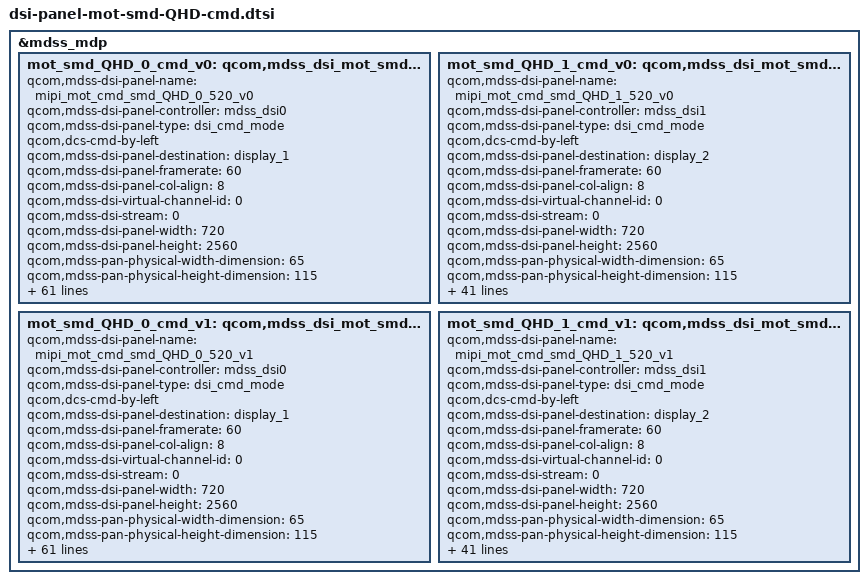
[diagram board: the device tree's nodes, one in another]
/* Copyright (c) 2012-2013, The Linux Foundation. All rights reserved.
 * Copyright (c) 2014 Motorola Mobility LLC
 *
 * This program is free software; you can redistribute it and/or modify
 * it under the terms of the GNU General Public License version 2 and
 * only version 2 as published by the Free Software Foundation.
 *
 * This program is distributed in the hope that it will be useful,
 * but WITHOUT ANY WARRANTY; without even the implied warranty of
 * MERCHANTABILITY or FITNESS FOR A PARTICULAR PURPOSE.  See the
 * GNU General Public License for more details.
 */

&mdss_mdp {
	mot_smd_QHD_0_cmd_v0: qcom,mdss_dsi_mot_smd_QHD_dualmipi0_cmd_v0 {
		qcom,mdss-dsi-panel-name = "mipi_mot_cmd_smd_QHD_0_520_v0";
		qcom,mdss-dsi-panel-controller = <&mdss_dsi0>;
		qcom,mdss-dsi-panel-type = "dsi_cmd_mode";
		qcom,dcs-cmd-by-left;
		qcom,mdss-dsi-panel-destination = "display_1";
		qcom,mdss-dsi-panel-framerate = <60>;
		qcom,mdss-dsi-panel-col-align = <8>;
		qcom,mdss-dsi-virtual-channel-id = <0>;
		qcom,mdss-dsi-stream = <0>;
		qcom,mdss-dsi-panel-width = <720>;
		qcom,mdss-dsi-panel-height = <2560>;
		qcom,mdss-pan-physical-width-dimension = <65>;
		qcom,mdss-pan-physical-height-dimension = <115>;
		qcom,mdss-dsi-panel-clockrate = <830000000>;
		qcom,mdss-dsi-h-front-porch = <120>;
		qcom,mdss-dsi-h-back-porch = <44>;
		qcom,mdss-dsi-h-pulse-width = <16>;
		qcom,mdss-dsi-h-sync-skew = <0>;
		qcom,mdss-dsi-v-back-porch = <4>;
		qcom,mdss-dsi-v-front-porch = <8>;
		qcom,mdss-dsi-v-pulse-width = <4>;
		qcom,mdss-dsi-h-left-border = <0>;
		qcom,mdss-dsi-h-right-border = <0>;
		qcom,mdss-dsi-v-top-border = <0>;
		qcom,mdss-dsi-v-bottom-border = <0>;
		qcom,mdss-dsi-bpp = <24>;
		qcom,mdss-dsi-underflow-color = <0xff>;
		qcom,mdss-dsi-border-color = <0>;
		qcom,mdss-dsi-h-sync-pulse = <0>;
		qcom,mdss-dsi-traffic-mode = "non_burst_sync_event";
		qcom,mdss-dsi-bllp-eof-power-mode;
		qcom,mdss-dsi-bllp-power-mode;
		qcom,mdss-dsi-lane-0-state;
		qcom,mdss-dsi-lane-1-state;
		qcom,mdss-dsi-lane-2-state;
		qcom,mdss-dsi-lane-3-state;
		qcom,mdss-dsi-tx-eot-append;
		qcom,mdss-dsi-panel-timings = [DB 34 22 00 62 66 28 36 2B 03
									04 00];

		qcom,mdss-dsi-hbm-on-command = [
			/* HBM setting in 2 MSB bits of reg 53 */
			15 01 00 00 00 00 02 53 e0];
		qcom,mdss-dsi-hbm-off-command = [
			15 01 00 00 00 00 02 53 20];

		qcom,mdss-dsi-reset-sequence = <1 11>;
		qcom,mdss-dsi-dis-reset-sequence = <0 3>;
		qcom,mdss-dsi-lp11-init;
		qcom,mdss-dsi-t-clk-post = <0x03>;
		qcom,mdss-dsi-t-clk-pre = <0x29>;
		qcom,mdss-dsi-bl-max-level = <255>;
		qcom,mdss-dsi-dma-trigger = "trigger_sw";
		qcom,mdss-dsi-mdp-trigger = "none";
		qcom,mdss-dsi-bl-pmic-control-type = "bl_ctrl_dcs";
		qcom,mdss-dsi-te-pin-select = <1>;
		qcom,mdss-dsi-te-v-sync-rd-ptr-irq-line = <0x2c>;
		qcom,mdss-dsi-te-v-sync-continues-lines = <0x3c>;
		qcom,mdss-dsi-te-dcs-command = <1>;
		qcom,mdss-dsi-te-check-enable;
		qcom,mdss-dsi-te-using-te-pin;
		qcom,mdss-dsi-on-command = [
			/* Unlock level 2 commands */
			39 01 00 00 01 00 03 F0 5A 5A
			/* Unlock level 3 commands */
			39 01 00 00 01 00 03 FC 5A 5A
			/* Adjust memory scan time */
			39 01 00 00 01 00 05 FF 00 00 20 00
			/* exit sleep mode */
			05 01 00 00 78 00 02 11 00
			/* enable_te */
			15 01 00 00 01 00 02 35 00
			/* disp_ctrl */
			39 01 00 00 01 00 02 53 20
			/* brightness_ctrl */
			15 01 00 00 01 00 02 51 00
			/* acl_enable_disable_settings */
			39 01 00 00 01 00 02 55 03
			/* Set index for P9 */
			39 01 00 00 01 00 02 B0 08
			/* Turn on memory retention */
			39 01 00 00 01 00 02 F4 03
			/* viewable region */
			39 01 00 00 00 00 05 30 00 00 09 ff
			/* normal col */
			39 01 00 00 00 00 05 2a 00 00 05 9f
			/* normal row */
			39 01 00 00 00 00 05 2b 00 00 09 ff
			/* display on */
			05 01 00 00 00 00 01 29];
		qcom,mdss-dsi-on-command-state = "dsi_lp_mode";
		qcom,mdss-dsi-off-command = [
			/* display_off */
			05 01 00 00 01 00 02 28 00
			/* enter sleep mode */
			05 01 00 00 78 00 02 10 00];
		qcom,mdss-dsi-off-command-state = "dsi_hs_mode";

		qcom,esd-check-enabled;
		qcom,mdss-dsi-panel-status-check-mode = "reg_read";
		qcom,mdss-dsi-panel-status-command = [06 01 00 01 00 00 01 0A];
		qcom,mdss-dsi-panel-status-command-state = "dsi_hs_mode";
		qcom,mdss-dsi-panel-status-value = <0x9c>;

	};

	mot_smd_QHD_1_cmd_v0: qcom,mdss_dsi_mot_smd_QHD_dualmipi1_cmd_v0 {
		qcom,mdss-dsi-panel-name = "mipi_mot_cmd_smd_QHD_1_520_v0";
		qcom,mdss-dsi-panel-controller = <&mdss_dsi1>;
		qcom,mdss-dsi-panel-type = "dsi_cmd_mode";
		qcom,dcs-cmd-by-left;
		qcom,mdss-dsi-panel-destination = "display_2";
		qcom,mdss-dsi-panel-framerate = <60>;
		qcom,mdss-dsi-panel-col-align = <8>;
		qcom,mdss-dsi-virtual-channel-id = <0>;
		qcom,mdss-dsi-stream = <0>;
		qcom,mdss-dsi-panel-width = <720>;
		qcom,mdss-dsi-panel-height = <2560>;
		qcom,mdss-pan-physical-width-dimension = <65>;
		qcom,mdss-pan-physical-height-dimension = <115>;
		qcom,mdss-dsi-panel-clockrate = <830000000>;
		qcom,mdss-dsi-h-front-porch = <120>;
		qcom,mdss-dsi-h-back-porch = <44>;
		qcom,mdss-dsi-h-pulse-width = <16>;
		qcom,mdss-dsi-h-sync-skew = <0>;
		qcom,mdss-dsi-v-back-porch = <4>;
		qcom,mdss-dsi-v-front-porch = <8>;
		qcom,mdss-dsi-v-pulse-width = <4>;
		qcom,mdss-dsi-h-left-border = <0>;
		qcom,mdss-dsi-h-right-border = <0>;
		qcom,mdss-dsi-v-top-border = <0>;
		qcom,mdss-dsi-v-bottom-border = <0>;
		qcom,mdss-dsi-bpp = <24>;
		qcom,mdss-dsi-underflow-color = <0xff>;
		qcom,mdss-dsi-border-color = <0>;

		qcom,mdss-dsi-h-sync-pulse = <0>;
		qcom,mdss-dsi-traffic-mode = "non_burst_sync_event";
		qcom,mdss-dsi-bllp-eof-power-mode;
		qcom,mdss-dsi-bllp-power-mode;
		qcom,mdss-dsi-lane-0-state;
		qcom,mdss-dsi-lane-1-state;
		qcom,mdss-dsi-lane-2-state;
		qcom,mdss-dsi-lane-3-state;
		qcom,mdss-dsi-tx-eot-append;
		qcom,mdss-dsi-panel-timings = [DB 34 22 00 62 66 28 36 2B 03
									04 00];
		qcom,mdss-dsi-lp11-init;
		qcom,mdss-dsi-t-clk-post = <0x03>;
		qcom,mdss-dsi-t-clk-pre = <0x29>;
		qcom,mdss-dsi-bl-max-level = <255>;
		qcom,mdss-dsi-dma-trigger = "trigger_sw";
		qcom,mdss-dsi-mdp-trigger = "none";
		qcom,mdss-dsi-bl-pmic-control-type = "bl_ctrl_dcs";
		qcom,mdss-dsi-te-pin-select = <1>;
		qcom,mdss-dsi-te-v-sync-rd-ptr-irq-line = <0x2c>;
		qcom,mdss-dsi-te-v-sync-continues-lines = <0x3c>;
		qcom,mdss-dsi-te-dcs-command = <1>;
		qcom,mdss-dsi-te-check-enable;
		qcom,mdss-dsi-te-using-te-pin;
	};

	mot_smd_QHD_0_cmd_v1: qcom,mdss_dsi_mot_smd_QHD_dualmipi0_cmd_v1 {
		qcom,mdss-dsi-panel-name = "mipi_mot_cmd_smd_QHD_0_520_v1";
		qcom,mdss-dsi-panel-controller = <&mdss_dsi0>;
		qcom,mdss-dsi-panel-type = "dsi_cmd_mode";
		qcom,dcs-cmd-by-left;
		qcom,mdss-dsi-panel-destination = "display_1";
		qcom,mdss-dsi-panel-framerate = <60>;
		qcom,mdss-dsi-panel-col-align = <8>;
		qcom,mdss-dsi-virtual-channel-id = <0>;
		qcom,mdss-dsi-stream = <0>;
		qcom,mdss-dsi-panel-width = <720>;
		qcom,mdss-dsi-panel-height = <2560>;
		qcom,mdss-pan-physical-width-dimension = <65>;
		qcom,mdss-pan-physical-height-dimension = <115>;
		qcom,mdss-dsi-panel-clockrate = <830000000>;
		qcom,mdss-dsi-h-front-porch = <120>;
		qcom,mdss-dsi-h-back-porch = <44>;
		qcom,mdss-dsi-h-pulse-width = <16>;
		qcom,mdss-dsi-h-sync-skew = <0>;
		qcom,mdss-dsi-v-back-porch = <4>;
		qcom,mdss-dsi-v-front-porch = <8>;
		qcom,mdss-dsi-v-pulse-width = <4>;
		qcom,mdss-dsi-h-left-border = <0>;
		qcom,mdss-dsi-h-right-border = <0>;
		qcom,mdss-dsi-v-top-border = <0>;
		qcom,mdss-dsi-v-bottom-border = <0>;
		qcom,mdss-dsi-bpp = <24>;
		qcom,mdss-dsi-underflow-color = <0xff>;
		qcom,mdss-dsi-border-color = <0>;
		qcom,mdss-dsi-h-sync-pulse = <0>;
		qcom,mdss-dsi-traffic-mode = "non_burst_sync_event";
		qcom,mdss-dsi-bllp-eof-power-mode;
		qcom,mdss-dsi-bllp-power-mode;
		qcom,mdss-dsi-lane-0-state;
		qcom,mdss-dsi-lane-1-state;
		qcom,mdss-dsi-lane-2-state;
		qcom,mdss-dsi-lane-3-state;
		qcom,mdss-dsi-tx-eot-append;
		qcom,mdss-dsi-panel-timings = [DB 34 22 00 62 66 28 36 2B 03
									04 00];

		qcom,mdss-dsi-hbm-on-command = [
			/* HBM setting in 2 MSB bits of reg 53 */
			15 01 00 00 00 00 02 53 e0];
		qcom,mdss-dsi-hbm-off-command = [
			15 01 00 00 00 00 02 53 20];

		qcom,mdss-dsi-reset-sequence = <1 11>;
		qcom,mdss-dsi-dis-reset-sequence = <0 3>;
		qcom,mdss-dsi-lp11-init;
		qcom,mdss-dsi-t-clk-post = <0x03>;
		qcom,mdss-dsi-t-clk-pre = <0x29>;
		qcom,mdss-dsi-bl-max-level = <255>;
		qcom,mdss-dsi-dma-trigger = "trigger_sw";
		qcom,mdss-dsi-mdp-trigger = "none";
		qcom,mdss-dsi-bl-pmic-control-type = "bl_ctrl_dcs";
		qcom,mdss-dsi-te-pin-select = <1>;
		qcom,mdss-dsi-te-v-sync-rd-ptr-irq-line = <0x2c>;
		qcom,mdss-dsi-te-v-sync-continues-lines = <0x3c>;
		qcom,mdss-dsi-te-dcs-command = <1>;
		qcom,mdss-dsi-te-check-enable;
		qcom,mdss-dsi-te-using-te-pin;
		qcom,mdss-dsi-on-command = [
			/* exit sleep mode */
			05 01 00 00 78 00 02 11 00
			/* enable_te */
			15 01 00 00 01 00 02 35 00
			/* disp_ctrl */
			39 01 00 00 01 00 02 53 20
			/* brightness_ctrl */
			15 01 00 00 01 00 02 51 00
			/* acl_enable_disable_settings */
			39 01 00 00 01 00 02 55 03
			/* Unlock level 2 commands */
			39 01 00 00 01 00 03 F0 5A 5A
			/* Set index for P9 */
			39 01 00 00 01 00 02 B0 08
			/* Turn on memory retention */
			39 01 00 00 01 00 02 F4 03
			/* viewable region */
			39 01 00 00 00 00 05 30 00 00 09 ff
			/* normal col */
			39 01 00 00 00 00 05 2a 00 00 05 9f
			/* normal row */
			39 01 00 00 00 00 05 2b 00 00 09 ff
			/* display on */
			29 01 00 00 00 00 02 29 00];
		qcom,mdss-dsi-on-command-state = "dsi_lp_mode";
		qcom,mdss-dsi-off-command = [
			/* display_off */
			05 01 00 00 01 00 02 28 00
			/* enter sleep mode */
			05 01 00 00 78 00 02 10 00];
		qcom,mdss-dsi-off-command-state = "dsi_hs_mode";

                qcom,esd-check-enabled;
                qcom,mdss-dsi-panel-status-check-mode = "reg_read";
                qcom,mdss-dsi-panel-status-command = [06 01 00 01 00 00 01 0A];
                qcom,mdss-dsi-panel-status-command-state = "dsi_hs_mode";
                qcom,mdss-dsi-panel-status-value = <0x9c>;
	};

	mot_smd_QHD_1_cmd_v1: qcom,mdss_dsi_mot_smd_QHD_dualmipi1_cmd_v1 {
		qcom,mdss-dsi-panel-name = "mipi_mot_cmd_smd_QHD_1_520_v1";
		qcom,mdss-dsi-panel-controller = <&mdss_dsi1>;
		qcom,mdss-dsi-panel-type = "dsi_cmd_mode";
		qcom,dcs-cmd-by-left;
		qcom,mdss-dsi-panel-destination = "display_2";
		qcom,mdss-dsi-panel-framerate = <60>;
		qcom,mdss-dsi-panel-col-align = <8>;
		qcom,mdss-dsi-virtual-channel-id = <0>;
		qcom,mdss-dsi-stream = <0>;
		qcom,mdss-dsi-panel-width = <720>;
		qcom,mdss-dsi-panel-height = <2560>;
		qcom,mdss-pan-physical-width-dimension = <65>;
		qcom,mdss-pan-physical-height-dimension = <115>;
		qcom,mdss-dsi-panel-clockrate = <830000000>;
		qcom,mdss-dsi-h-front-porch = <120>;
		qcom,mdss-dsi-h-back-porch = <44>;
		qcom,mdss-dsi-h-pulse-width = <16>;
		qcom,mdss-dsi-h-sync-skew = <0>;
		qcom,mdss-dsi-v-back-porch = <4>;
		qcom,mdss-dsi-v-front-porch = <8>;
		qcom,mdss-dsi-v-pulse-width = <4>;
		qcom,mdss-dsi-h-left-border = <0>;
		qcom,mdss-dsi-h-right-border = <0>;
		qcom,mdss-dsi-v-top-border = <0>;
		qcom,mdss-dsi-v-bottom-border = <0>;
		qcom,mdss-dsi-bpp = <24>;
		qcom,mdss-dsi-underflow-color = <0xff>;
		qcom,mdss-dsi-border-color = <0>;

		qcom,mdss-dsi-h-sync-pulse = <0>;
		qcom,mdss-dsi-traffic-mode = "non_burst_sync_event";
		qcom,mdss-dsi-bllp-eof-power-mode;
		qcom,mdss-dsi-bllp-power-mode;
		qcom,mdss-dsi-lane-0-state;
		qcom,mdss-dsi-lane-1-state;
		qcom,mdss-dsi-lane-2-state;
		qcom,mdss-dsi-lane-3-state;
		qcom,mdss-dsi-tx-eot-append;
		qcom,mdss-dsi-panel-timings = [DB 34 22 00 62 66 28 36 2B 03
									04 00];
		qcom,mdss-dsi-lp11-init;
		qcom,mdss-dsi-t-clk-post = <0x03>;
		qcom,mdss-dsi-t-clk-pre = <0x29>;
		qcom,mdss-dsi-bl-max-level = <255>;
		qcom,mdss-dsi-dma-trigger = "trigger_sw";
		qcom,mdss-dsi-mdp-trigger = "none";
		qcom,mdss-dsi-bl-pmic-control-type = "bl_ctrl_dcs";
		qcom,mdss-dsi-te-pin-select = <1>;
		qcom,mdss-dsi-te-v-sync-rd-ptr-irq-line = <0x2c>;
		qcom,mdss-dsi-te-v-sync-continues-lines = <0x3c>;
		qcom,mdss-dsi-te-dcs-command = <1>;
		qcom,mdss-dsi-te-check-enable;
		qcom,mdss-dsi-te-using-te-pin;
	};
};
